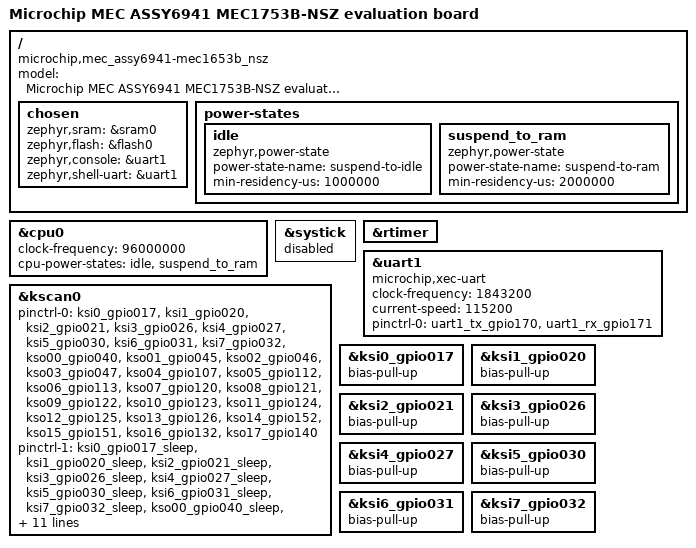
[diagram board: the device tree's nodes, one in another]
/*
 * Copyright (c) 2025, Microchip Technology Inc.
 *
 * SPDX-License-Identifier: Apache-2.0
 */

/dts-v1/;

#include <microchip/mec/mec5_mec1653bnsz.dtsi>
#include <microchip/mec/mec5/mec1653b-b0-pinctrl.dtsi>

/ {
	model = "Microchip MEC ASSY6941 MEC1753B-NSZ evaluation board";
	compatible = "microchip,mec_assy6941-mec1653b_nsz";

	chosen {
		zephyr,sram = &sram0;
		zephyr,flash = &flash0;
		zephyr,console = &uart1;
		zephyr,shell-uart = &uart1;
	};

	power-states {
		idle: idle {
			compatible = "zephyr,power-state";
			power-state-name = "suspend-to-idle";
			min-residency-us = <1000000>;
		};

		suspend_to_ram: suspend_to_ram {
			compatible = "zephyr,power-state";
			power-state-name = "suspend-to-ram";
			min-residency-us = <2000000>;
		};
	};
};

&cpu0 {
	clock-frequency = <96000000>;
	status = "okay";
	cpu-power-states = <&idle &suspend_to_ram>;
};

/* Disable ARM SysTick kernel timer driver */
&systick {
	status = "disabled";
};

/* Enable MCHP kernel timer driver using 32KHz RTOS timer and 1MHz basic timer */
&rtimer {
	status = "okay";
};

&uart1 {
	compatible = "microchip,xec-uart";
	status = "okay";
	clock-frequency = <1843200>;
	current-speed = <115200>;
	pinctrl-0 = <&uart1_tx_gpio170 &uart1_rx_gpio171>;
	pinctrl-names = "default";
};

&kscan0 {
	pinctrl-0 = <&ksi0_gpio017 &ksi1_gpio020 &ksi2_gpio021 &ksi3_gpio026
		     &ksi4_gpio027 &ksi5_gpio030 &ksi6_gpio031 &ksi7_gpio032
		     &kso00_gpio040 &kso01_gpio045 &kso02_gpio046 &kso03_gpio047
		     &kso04_gpio107 &kso05_gpio112 &kso06_gpio113 &kso07_gpio120
		     &kso08_gpio121 &kso09_gpio122 &kso10_gpio123 &kso11_gpio124
		     &kso12_gpio125 &kso13_gpio126 &kso14_gpio152 &kso15_gpio151
		     &kso16_gpio132 &kso17_gpio140>;
	pinctrl-1 = <&ksi0_gpio017_sleep &ksi1_gpio020_sleep &ksi2_gpio021_sleep
		     &ksi3_gpio026_sleep &ksi4_gpio027_sleep &ksi5_gpio030_sleep
		     &ksi6_gpio031_sleep &ksi7_gpio032_sleep &kso00_gpio040_sleep
		     &kso01_gpio045_sleep &kso02_gpio046_sleep &kso03_gpio047_sleep
		     &kso04_gpio107_sleep &kso05_gpio112_sleep &kso06_gpio113_sleep
		     &kso07_gpio120_sleep &kso08_gpio121_sleep &kso09_gpio122_sleep
		     &kso10_gpio123_sleep &kso11_gpio124_sleep &kso12_gpio125_sleep
		     &kso13_gpio126_sleep &kso14_gpio152_sleep &kso15_gpio151_sleep
		     &kso16_gpio132_sleep &kso17_gpio140_sleep>;
	pinctrl-names = "default", "sleep";
	row-size = <8>;
	col-size = <18>;
};

&ksi0_gpio017 {
	bias-pull-up;
};

&ksi1_gpio020 {
	bias-pull-up;
};

&ksi2_gpio021 {
	bias-pull-up;
};

&ksi3_gpio026 {
	bias-pull-up;
};

&ksi4_gpio027 {
	bias-pull-up;
};

&ksi5_gpio030 {
	bias-pull-up;
};

&ksi6_gpio031 {
	bias-pull-up;
};

&ksi7_gpio032 {
	bias-pull-up;
};
